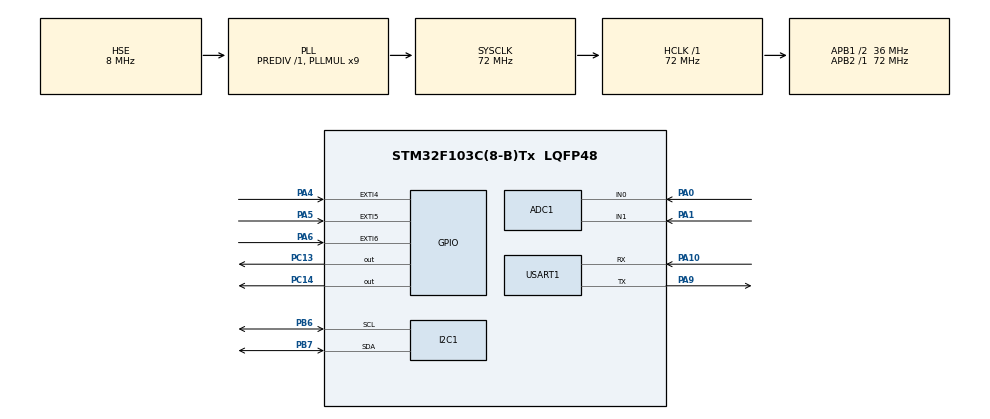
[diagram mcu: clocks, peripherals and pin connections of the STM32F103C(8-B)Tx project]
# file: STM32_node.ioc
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ADC1.Channel-0\#ChannelRegularConversion=ADC_CHANNEL_TEMPSENSOR
ADC1.Channel-1\#ChannelRegularConversion=ADC_CHANNEL_0
ADC1.Channel-2\#ChannelRegularConversion=ADC_CHANNEL_1
ADC1.ContinuousConvMode=ENABLE
ADC1.NbrOfConversion=3
ADC1.NbrOfConversionFlag=1
ADC1.Rank-0\#ChannelRegularConversion=1
ADC1.Rank-1\#ChannelRegularConversion=2
ADC1.Rank-2\#ChannelRegularConversion=3
ADC1.SamplingTime-0\#ChannelRegularConversion=ADC_SAMPLETIME_239CYCLES_5
ADC1.SamplingTime-1\#ChannelRegularConversion=ADC_SAMPLETIME_7CYCLES_5
ADC1.SamplingTime-2\#ChannelRegularConversion=ADC_SAMPLETIME_7CYCLES_5
ADC1.master=1
Dma.ADC1.0.Direction=DMA_PERIPH_TO_MEMORY
Dma.ADC1.0.Instance=DMA1_Channel1
Dma.ADC1.0.MemDataAlignment=DMA_MDATAALIGN_HALFWORD
Dma.ADC1.0.MemInc=DMA_MINC_ENABLE
Dma.ADC1.0.Mode=DMA_CIRCULAR
Dma.ADC1.0.PeriphDataAlignment=DMA_PDATAALIGN_HALFWORD
Dma.ADC1.0.PeriphInc=DMA_PINC_DISABLE
Dma.ADC1.0.Priority=DMA_PRIORITY_LOW
Dma.Request0=ADC1
FREERTOS.Tasks01=defaultTask,0,128,StartDefaultTask,Default,NULL,Dynamic,NULL,NULL
I2C1.I2C_Mode=I2C_Fast
Mcu.Family=STM32F1
Mcu.Name=STM32F103C(8-B)Tx
Mcu.Package=LQFP48
NVIC.ADC1_2_IRQn=true\:5\:0\:false\:false\:true\:true\:true\:true\:true
NVIC.DMA1_Channel1_IRQn=true\:5\:0\:false\:false\:true\:true\:false\:true\:true
NVIC.EXTI4_IRQn=true\:5\:0\:true\:false\:true\:true\:true\:true\:true
NVIC.EXTI9_5_IRQn=true\:5\:0\:true\:false\:true\:true\:true\:true\:true
NVIC.PriorityGroup=NVIC_PRIORITYGROUP_4
NVIC.TIM1_UP_IRQn=true\:15\:0\:false\:false\:true\:false\:false\:true\:true
NVIC.TimeBase=TIM1_UP_IRQn
NVIC.TimeBaseIP=TIM1
NVIC.USART1_IRQn=true\:5\:0\:false\:false\:true\:true\:true\:true\:true
PA0-WKUP.Signal=ADCx_IN0
PA1.Signal=ADCx_IN1
PA10.Mode=Asynchronous
PA10.Signal=USART1_RX
PA13.Mode=Serial_Wire
PA13.Signal=SYS_JTMS-SWDIO
PA14.Mode=Serial_Wire
PA14.Signal=SYS_JTCK-SWCLK
PA4.Signal=GPXTI4
PA5.Signal=GPXTI5
PA6.Signal=GPXTI6
PA9.Mode=Asynchronous
PA9.Signal=USART1_TX
PB6.Mode=I2C
PB6.Signal=I2C1_SCL
PB7.Mode=I2C
PB7.Signal=I2C1_SDA
PC13-TAMPER-RTC.Signal=GPIO_Output
PC14-OSC32_IN.Signal=GPIO_Output
PD0-OSC_IN.Mode=HSE-External-Oscillator
PD0-OSC_IN.Signal=RCC_OSC_IN
PD1-OSC_OUT.Mode=HSE-External-Oscillator
PD1-OSC_OUT.Signal=RCC_OSC_OUT
ProjectManager.HeapSize=0x200
ProjectManager.StackSize=0x400
ProjectManager.TargetToolchain=Makefile
RCC.ADCPresc=RCC_ADCPCLK2_DIV6
RCC.AHBFreq_Value=72000000
RCC.APB1CLKDivider=RCC_HCLK_DIV2
RCC.APB1Freq_Value=36000000
RCC.APB1TimFreq_Value=72000000
RCC.APB2Freq_Value=72000000
RCC.APB2TimFreq_Value=72000000
RCC.HCLKFreq_Value=72000000
RCC.PLLMUL=RCC_PLL_MUL9
RCC.PLLSourceVirtual=RCC_PLLSOURCE_HSE
RCC.SYSCLKFreq_VALUE=72000000
RCC.SYSCLKSource=RCC_SYSCLKSOURCE_PLLCLK
RCC.USBFreq_Value=72000000
SH.ADCx_IN0.0=ADC1_IN0,IN0
SH.ADCx_IN1.0=ADC1_IN1,IN1
USART1.VirtualMode=VM_ASYNC
VP_ADC1_TempSens_Input.Mode=IN-TempSens
VP_FREERTOS_VS_CMSIS_V1.Mode=CMSIS_V1
VP_SYS_VS_tim1.Mode=TIM1
board=custom

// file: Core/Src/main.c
/* USER CODE BEGIN Header */
/**
  ******************************************************************************
  * @file           : main.c
  * @brief          : Main program body
  ******************************************************************************
  * @attention
  *
  * Copyright (c) 2025 STMicroelectronics.
  * All rights reserved.
  *
  * This software is licensed under terms that can be found in the LICENSE file
  * in the root directory of this software component.
  * If no LICENSE file comes with this software, it is provided AS-IS.
  *
  ******************************************************************************
  */
/* USER CODE END Header */
#include "main.h"

/* USER CODE BEGIN Includes */
#include "tasks_functions.h"
#include "ssd1306.h"

/* USER CODE END Includes */

ADC_HandleTypeDef hadc1;
DMA_HandleTypeDef hdma_adc1;
DMA_HandleTypeDef hdma_usart1_rx;
DMA_HandleTypeDef hdma_usart1_tx;

I2C_HandleTypeDef hi2c1;

UART_HandleTypeDef huart1;

/* USER CODE BEGIN PV */
extern volatile uint32_t adcValues[ADC_CH_NUM];

/* USER CODE END PV */

void SystemClock_Config(void);
static void MX_GPIO_Init(void);
static void MX_DMA_Init(void);
static void MX_ADC1_Init(void);
static void MX_USART1_UART_Init(void);
static void MX_I2C1_Init(void);

int main(void)
{

  /* MCU Configuration--------------------------------------------------------*/

  /* Reset of all peripherals, Initializes the Flash interface and the Systick. */
  HAL_Init();

  /* Configure the system clock */
  SystemClock_Config();

  /* Initialize all configured peripherals */
  MX_GPIO_Init();
  MX_DMA_Init();
  MX_ADC1_Init();
  MX_USART1_UART_Init();
  MX_I2C1_Init();
  /* USER CODE BEGIN 2 */
  ssd1306_Init();
  ssd1306_SetCursor(2, 10);
  ssd1306_WriteString("Starting", Font_6x8, White);
  ssd1306_UpdateScreen();
  //HAL_Delay(200);

  /* Start ADC DMA */
  ssd1306_Fill(Black);
  ssd1306_SetCursor(2, 10);
  ssd1306_WriteString("Starting ADC DMA", Font_6x8, White);
  ssd1306_UpdateScreen();
  //HAL_Delay(200);
  ssd1306_SetCursor(105, 10);
  if(HAL_ADC_Start_DMA(&hadc1, (uint32_t*)adcValues, ADC_CH_NUM) != HAL_OK)
  {
    ssd1306_WriteString("failed", Font_6x8, White);
    ssd1306_UpdateScreen();
    Error_Handler();
  }
  else
  {
    ssd1306_WriteString("OK", Font_6x8, White);
    ssd1306_UpdateScreen();
  }
  //HAL_Delay(200);

  /* Start UART Rx in interrupt mode*/
  ssd1306_Fill(Black);
  ssd1306_SetCursor(2, 10);
  ssd1306_WriteString("Starting UART IT", Font_6x8, White);
  ssd1306_UpdateScreen();
  //HAL_Delay(1000);
  ssd1306_SetCursor(105, 10);
  if(HAL_UART_Receive_DMA(&huart1, (uint8_t*)RxBuffer, sizeof(RxBuffer)) != HAL_OK)
  {
    ssd1306_WriteString("failed", Font_6x8, White);
    ssd1306_UpdateScreen();
    Error_Handler();
  }
  else
  {
    ssd1306_WriteString("OK", Font_6x8, White);
    ssd1306_UpdateScreen();
  }
  //HAL_Delay(1000);

  /* RTOS setup */
  ssd1306_Fill(Black);
  ssd1306_SetCursor(2, 10);
  ssd1306_WriteString("Setting up RTOS", Font_6x8, White);
  ssd1306_UpdateScreen();
  //HAL_Delay(1000);

  ssd1306_SetCursor(100, 10);
  if(!setupRTOS())
  {
    ssd1306_WriteString("failed", Font_6x8, White);
    ssd1306_UpdateScreen();
    Error_Handler();
  }
  else
  {
    ssd1306_WriteString("OK", Font_6x8, White);
    ssd1306_UpdateScreen();
  }
  /* USER CODE END 2 */

  /* Start scheduler */
  vTaskStartScheduler();

  /* We should never get here as control is now taken by the scheduler */

  /* Infinite loop */
  while (1)
  {
  }
}

void SystemClock_Config(void)
{
  RCC_OscInitTypeDef RCC_OscInitStruct = {0};
  RCC_ClkInitTypeDef RCC_ClkInitStruct = {0};
  RCC_PeriphCLKInitTypeDef PeriphClkInit = {0};

  /** Initializes the RCC Oscillators according to the specified parameters
  * in the RCC_OscInitTypeDef structure.
  */
  RCC_OscInitStruct.OscillatorType = RCC_OSCILLATORTYPE_HSE;
  RCC_OscInitStruct.HSEState = RCC_HSE_ON;
  RCC_OscInitStruct.HSEPredivValue = RCC_HSE_PREDIV_DIV1;
  RCC_OscInitStruct.HSIState = RCC_HSI_ON;
  RCC_OscInitStruct.PLL.PLLState = RCC_PLL_ON;
  RCC_OscInitStruct.PLL.PLLSource = RCC_PLLSOURCE_HSE;
  RCC_OscInitStruct.PLL.PLLMUL = RCC_PLL_MUL9;
  if (HAL_RCC_OscConfig(&RCC_OscInitStruct) != HAL_OK)
  {
    Error_Handler();
  }

  /** Initializes the CPU, AHB and APB buses clocks
  */
  RCC_ClkInitStruct.ClockType = RCC_CLOCKTYPE_HCLK|RCC_CLOCKTYPE_SYSCLK
                              |RCC_CLOCKTYPE_PCLK1|RCC_CLOCKTYPE_PCLK2;
  RCC_ClkInitStruct.SYSCLKSource = RCC_SYSCLKSOURCE_PLLCLK;
  RCC_ClkInitStruct.AHBCLKDivider = RCC_SYSCLK_DIV1;
  RCC_ClkInitStruct.APB1CLKDivider = RCC_HCLK_DIV2;
  RCC_ClkInitStruct.APB2CLKDivider = RCC_HCLK_DIV1;

  if (HAL_RCC_ClockConfig(&RCC_ClkInitStruct, FLASH_LATENCY_2) != HAL_OK)
  {
    Error_Handler();
  }
  PeriphClkInit.PeriphClockSelection = RCC_PERIPHCLK_ADC;
  PeriphClkInit.AdcClockSelection = RCC_ADCPCLK2_DIV6;
  if (HAL_RCCEx_PeriphCLKConfig(&PeriphClkInit) != HAL_OK)
  {
    Error_Handler();
  }
}

static void MX_ADC1_Init(void)
{

  ADC_ChannelConfTypeDef sConfig = {0};

  /** Common config
  */
  hadc1.Instance = ADC1;
  hadc1.Init.ScanConvMode = ADC_SCAN_ENABLE;
  hadc1.Init.ContinuousConvMode = ENABLE;
  hadc1.Init.DiscontinuousConvMode = DISABLE;
  hadc1.Init.ExternalTrigConv = ADC_SOFTWARE_START;
  hadc1.Init.DataAlign = ADC_DATAALIGN_RIGHT;
  hadc1.Init.NbrOfConversion = 3;
  if (HAL_ADC_Init(&hadc1) != HAL_OK)
  {
    Error_Handler();
  }

  /** Configure Regular Channel
  */
  sConfig.Channel = ADC_CHANNEL_TEMPSENSOR;
  sConfig.Rank = ADC_REGULAR_RANK_1;
  sConfig.SamplingTime = ADC_SAMPLETIME_71CYCLES_5;
  if (HAL_ADC_ConfigChannel(&hadc1, &sConfig) != HAL_OK)
  {
    Error_Handler();
  }

  /** Configure Regular Channel
  */
  sConfig.Channel = ADC_CHANNEL_0;
  sConfig.Rank = ADC_REGULAR_RANK_2;
  sConfig.SamplingTime = ADC_SAMPLETIME_71CYCLES_5;
  if (HAL_ADC_ConfigChannel(&hadc1, &sConfig) != HAL_OK)
  {
    Error_Handler();
  }

  /** Configure Regular Channel
  */
  sConfig.Channel = ADC_CHANNEL_1;
  sConfig.Rank = ADC_REGULAR_RANK_3;
  if (HAL_ADC_ConfigChannel(&hadc1, &sConfig) != HAL_OK)
  {
    Error_Handler();
  }

}

static void MX_I2C1_Init(void)
{

  hi2c1.Instance = I2C1;
  hi2c1.Init.ClockSpeed = 400000;
  hi2c1.Init.DutyCycle = I2C_DUTYCYCLE_2;
  hi2c1.Init.OwnAddress1 = 0;
  hi2c1.Init.AddressingMode = I2C_ADDRESSINGMODE_7BIT;
  hi2c1.Init.DualAddressMode = I2C_DUALADDRESS_DISABLE;
  hi2c1.Init.OwnAddress2 = 0;
  hi2c1.Init.GeneralCallMode = I2C_GENERALCALL_DISABLE;
  hi2c1.Init.NoStretchMode = I2C_NOSTRETCH_DISABLE;
  if (HAL_I2C_Init(&hi2c1) != HAL_OK)
  {
    Error_Handler();
  }

}

static void MX_USART1_UART_Init(void)
{

  huart1.Instance = USART1;
  huart1.Init.BaudRate = 115200;
  huart1.Init.WordLength = UART_WORDLENGTH_8B;
  huart1.Init.StopBits = UART_STOPBITS_1;
  huart1.Init.Parity = UART_PARITY_NONE;
  huart1.Init.Mode = UART_MODE_TX_RX;
  huart1.Init.HwFlowCtl = UART_HWCONTROL_NONE;
  huart1.Init.OverSampling = UART_OVERSAMPLING_16;
  if (HAL_UART_Init(&huart1) != HAL_OK)
  {
    Error_Handler();
  }

}

static void MX_DMA_Init(void)
{

  /* DMA controller clock enable */
  __HAL_RCC_DMA1_CLK_ENABLE();

  /* DMA interrupt init */
  /* DMA1_Channel1_IRQn interrupt configuration */
  HAL_NVIC_SetPriority(DMA1_Channel1_IRQn, 5, 0);
  HAL_NVIC_EnableIRQ(DMA1_Channel1_IRQn);

  /* DMA1_Channel4_IRQn interrupt configuration */
  HAL_NVIC_SetPriority(DMA1_Channel4_IRQn, 5, 0);
  HAL_NVIC_EnableIRQ(DMA1_Channel4_IRQn);

  /* DMA1_Channel5_IRQn interrupt configuration */
  HAL_NVIC_SetPriority(DMA1_Channel5_IRQn, 5, 0);
  HAL_NVIC_EnableIRQ(DMA1_Channel5_IRQn);

}

static void MX_GPIO_Init(void)
{
  GPIO_InitTypeDef GPIO_InitStruct = {0};

  /* GPIO Ports Clock Enable */
  __HAL_RCC_GPIOC_CLK_ENABLE();
  __HAL_RCC_GPIOD_CLK_ENABLE();
  __HAL_RCC_GPIOA_CLK_ENABLE();
  __HAL_RCC_GPIOB_CLK_ENABLE();

  /*Configure GPIO pin Output Level */
  HAL_GPIO_WritePin(GPIOC, GPIO_PIN_13|GPIO_PIN_14|GPIO_PIN_15, LED_OFF);

  /*Configure GPIO pins : PC13 PC14 */
  GPIO_InitStruct.Pin = GPIO_PIN_13|GPIO_PIN_14|GPIO_PIN_15;
  GPIO_InitStruct.Mode = GPIO_MODE_OUTPUT_PP;
  GPIO_InitStruct.Pull = GPIO_NOPULL;
  GPIO_InitStruct.Speed = GPIO_SPEED_FREQ_LOW;
  HAL_GPIO_Init(GPIOC, &GPIO_InitStruct);

  /*Configure GPIO pins : PA4 PA5 PA6 */
  GPIO_InitStruct.Pin = GPIO_PIN_4|GPIO_PIN_5|GPIO_PIN_6;
  GPIO_InitStruct.Mode = GPIO_MODE_IT_FALLING;
  GPIO_InitStruct.Pull = GPIO_NOPULL;
  HAL_GPIO_Init(GPIOA, &GPIO_InitStruct);

  /* EXTI interrupt init*/
  HAL_NVIC_SetPriority(EXTI4_IRQn, 6, 0);
  HAL_NVIC_EnableIRQ(EXTI4_IRQn);

  HAL_NVIC_SetPriority(EXTI9_5_IRQn, 6, 0);
  HAL_NVIC_EnableIRQ(EXTI9_5_IRQn);

}

void HAL_TIM_PeriodElapsedCallback(TIM_HandleTypeDef *htim)
{
  if (htim->Instance == TIM1) {
    HAL_IncTick();
  }
}

void Error_Handler(void)
{
  __disable_irq();
  while (1)
  {
  }
}
